# STM32WL5x_CM0P register map
File version: 1.9
CPU: CM0 r0p1, little endian, MPU, no FPU, 4 interrupt priority bits
Registers are 32-bit, read-write, reset 0x0 unless marked. A register's access mark holds for its fields unless they carry their own. Offsets are from the block's base; [hi:lo] are bit positions; {n}, {i} and the like mark numbered series.

## MPU — Memory protection unit
Base 0xE000ED90
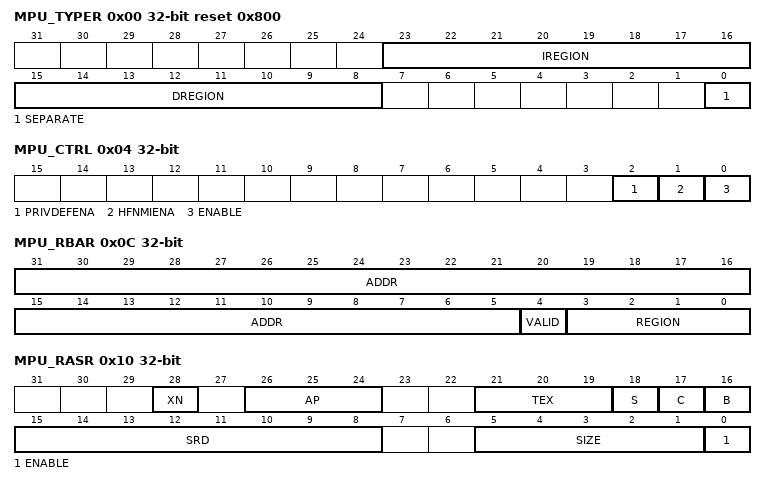
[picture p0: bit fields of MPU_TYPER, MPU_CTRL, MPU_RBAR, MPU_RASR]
0x00 MPU_TYPER ro reset 0x800 — MPU type register
  [23:16] IREGION — Number of MPU instruction regions
  [15:8] DREGION — Number of MPU data regions
  [0] SEPARATE — Separate flag
0x04 MPU_CTRL ro — MPU control register
  [2] PRIVDEFENA — Enable priviliged software access to default memory map
  [1] HFNMIENA — Enables the operation of MPU during hard fault
  [0] ENABLE — Enables the MPU
0x08 MPU_RNR — MPU region number register
  [7:0] REGION — MPU region
0x0C MPU_RBAR — MPU region base address register
  [31:5] ADDR — Region base address field
  [4] VALID — MPU region number valid
  [3:0] REGION — MPU region field
0x10 MPU_RASR — MPU region attribute and size register
  [28] XN — Instruction access disable bit
  [26:24] AP — Access permission
  [21:19] TEX — memory attribute
  [18] S — Shareable memory attribute
  [17] C — memory attribute
  [16] B — memory attribute
  [15:8] SRD — Subregion disable bits
  [5:1] SIZE — Size of the MPU protection region
  [0] ENABLE — Region enable bit.

## NVIC — Nested Vectored Interrupt Controller
Base 0xE000E100
0x00 ISER0 — Interrupt Set-Enable Register
  [31:0] SETENA
0x80 ICER0 — Interrupt Clear-Enable Register
  [31:0] CLRENA
0x100 ISPR0 — Interrupt Set-Pending Register
  [31:0] SETPEND
0x180 ICPR0 — Interrupt Clear-Pending Register
  [31:0] CLRPEND
0x200 IABR0 ro — Interrupt Active Bit Register
  [31:0] ACTIVE
0x204 IABR1 ro — Interrupt Active Bit Register
  [31:0] ACTIVE
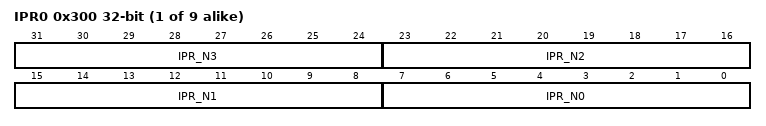
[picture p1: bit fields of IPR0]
{0x300+4i} IPR{i} (i=0..8) — Interrupt Priority Register
  [8n+7:8n] IPR_N{n} (n=0..3)

## NVIC_STIR — Nested vectored interrupt controller
Base 0xE000EF00
0x00 STIR — Software trigger interrupt register
  [8:0] INTID — Software generated interrupt ID

## PKA — Public key accelerator
Base 0x58002000
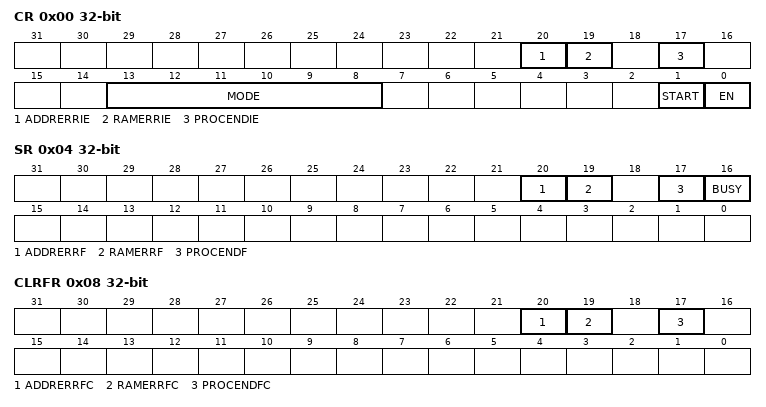
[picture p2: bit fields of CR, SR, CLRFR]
0x00 CR — control register
  [20] ADDRERRIE — Address error interrupt enable
  [19] RAMERRIE — RAM error interrupt enable
  [17] PROCENDIE
  [13:8] MODE — PKA operation code
  [1] START — start the operation
  [0] EN — PKA enable.
0x04 SR ro — status register
  [20] ADDRERRF — Address error flag
  [19] RAMERRF — PKA RAM error flag
  [17] PROCENDF — PKA End of Operation flag
  [16] BUSY — PKA operation is in progressThis bit is set to 1 whenever START bit in the PKA_CR is set. It is automatically cleared when the computation is complete, meaning that PKA RAM can be safely accessed and a new operation can be started.
0x08 CLRFR wo — clear flag register
  [20] ADDRERRFC — Clear Address error flag
  [19] RAMERRFC — Clear PKA RAM error flag
  [17] PROCENDFC — Clear PKA End of Operation flag

## RNG — True random number generator
Base 0x58001000
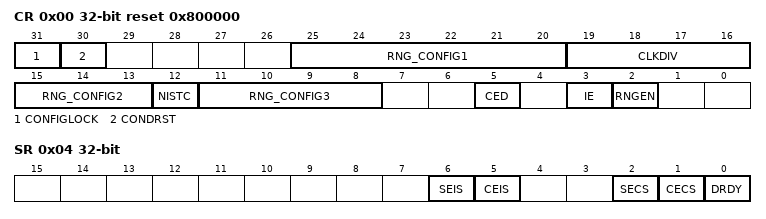
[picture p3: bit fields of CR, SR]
0x00 CR reset 0x800000 — control register
  [31] CONFIGLOCK
  [30] CONDRST — Conditioning soft reset
  [25:20] RNG_CONFIG1
  [19:16] CLKDIV
  [15:13] RNG_CONFIG2
  [12] NISTC
  [11:8] RNG_CONFIG3
  [5] CED — Interrupt Enable
  [3] IE — Interrupt Enable
  [2] RNGEN — True random number generator enable
0x04 SR access per field — status register
  [6] SEIS rw — Seed error interrupt status
  [5] CEIS rw — Clock error interrupt status
  [2] SECS ro — Seed error current status
  [1] CECS ro — Clock error current status
  [0] DRDY ro — Data Ready
0x08 DR ro — data register
  [31:0] RNDATA — Random data
0x10 HTCR reset 0x5A4E — health test control register
  [31:0] HTCFG — health test configuration

## SCB_ACTRL — System control block ACTLR
Base 0xE000E008
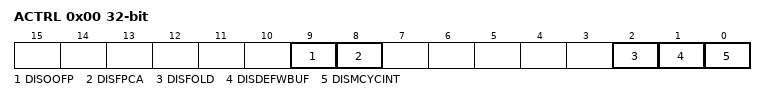
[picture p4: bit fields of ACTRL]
0x00 ACTRL — Auxiliary control register
  [9] DISOOFP, [8] DISFPCA, [2] DISFOLD, [1] DISDEFWBUF, [0] DISMCYCINT

## SPI1 — Serial peripheral interface/Inter-IC sound
Base 0x40013000
Same registers: SPI2 0x40003800, SPI3 0x58010000
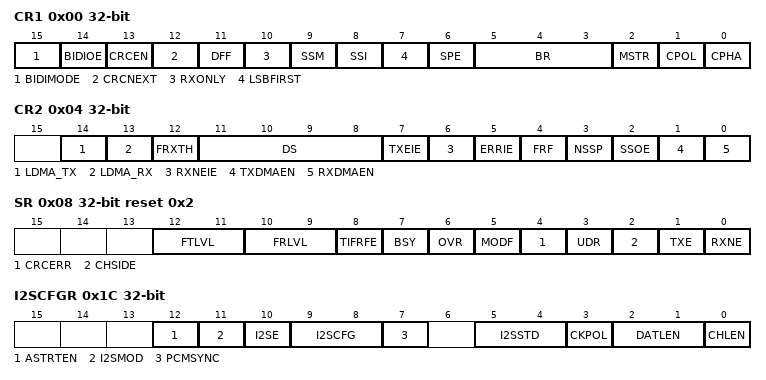
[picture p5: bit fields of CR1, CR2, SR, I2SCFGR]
0x00 CR1 — control register 1
  [15] BIDIMODE — Bidirectional data mode enable
  [14] BIDIOE — Output enable in bidirectional mode
  [13] CRCEN — Hardware CRC calculation enable
  [12] CRCNEXT — CRC transfer next
  [11] DFF — Data frame format
  [10] RXONLY — Receive only
  [9] SSM — Software slave management
  [8] SSI — Internal slave select
  [7] LSBFIRST — Frame format
  [6] SPE — SPI enable
  [5:3] BR — Baud rate control
  [2] MSTR — Master selection
  [1] CPOL — Clock polarity
  [0] CPHA — Clock phase
0x04 CR2 — control register 2
  [14] LDMA_TX — Last DMA transfer for transmission
  [13] LDMA_RX — Last DMA transfer for reception
  [12] FRXTH — FIFO reception threshold
  [11:8] DS — Data size
  [7] TXEIE — Tx buffer empty interrupt enable
  [6] RXNEIE — RX buffer not empty interrupt enable
  [5] ERRIE — Error interrupt enable
  [4] FRF — Frame format
  [3] NSSP — NSS pulse management
  [2] SSOE — SS output enable
  [1] TXDMAEN — Tx buffer DMA enable
  [0] RXDMAEN — Rx buffer DMA enable
0x08 SR access per field reset 0x2 — status register
  [12:11] FTLVL ro — FIFO transmission level
  [10:9] FRLVL ro — FIFO reception level
  [8] TIFRFE ro — TI frame format error
  [7] BSY ro — Busy flag
  [6] OVR ro — Overrun flag
  [5] MODF ro — Mode fault
  [4] CRCERR rw — CRC error flag
  [3] UDR ro
  [2] CHSIDE ro
  [1] TXE ro — Transmit buffer empty
  [0] RXNE ro — Receive buffer not empty
0x0C DR — data register
  [15:0] DR — Data register
0x10 CRCPR reset 0x7 — CRC polynomial register
  [15:0] CRCPOLY
0x14 RXCRCR ro — RX CRC register
  [15:0] RxCRC
0x18 TXCRCR ro — TX CRC register
  [15:0] TxCRC
0x1C I2SCFGR — configuration register
  [12] ASTRTEN, [11] I2SMOD, [10] I2SE, [9:8] I2SCFG, [7] PCMSYNC, [5:4] I2SSTD, [3] CKPOL, [2:1] DATLEN, [0] CHLEN
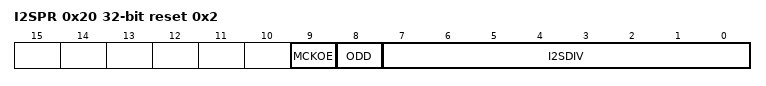
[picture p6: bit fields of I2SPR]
0x20 I2SPR reset 0x2 — prescaler register
  [9] MCKOE, [8] ODD, [7:0] I2SDIV
